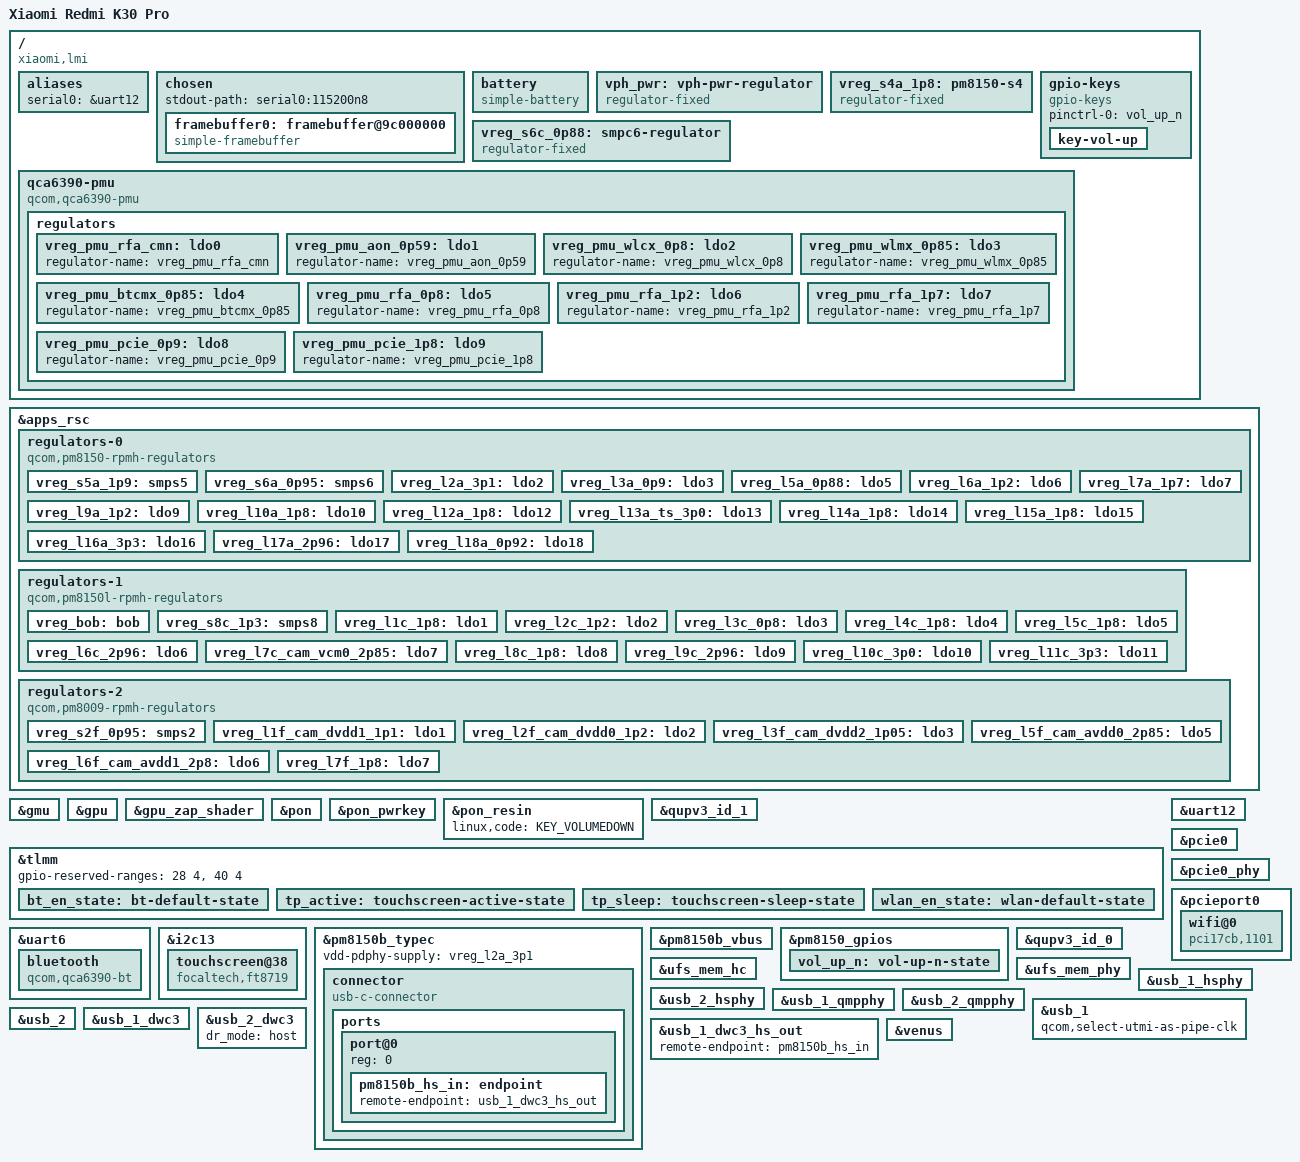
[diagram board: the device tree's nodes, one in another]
// SPDX-License-Identifier: BSD-3-Clause
/*
 * Copyright (c) 2020, The Linux Foundation. All rights reserved.
 * Copyright (c) 2026 OpenAI
 */

/dts-v1/;

#include <dt-bindings/arm/qcom,ids.h>
#include <dt-bindings/interrupt-controller/irq.h>
#include <dt-bindings/regulator/qcom,rpmh-regulator.h>
#include <dt-bindings/usb/pd.h>
#include "sm8250.dtsi"
#include "pm8150.dtsi"
#include "pm8150b.dtsi"
#include "pm8150l.dtsi"

/ {
	model = "Xiaomi Redmi K30 Pro";
	compatible = "xiaomi,lmi", "qcom,sm8250";

	/* Required by the Xiaomi bootloader to match this SM8250 board. */
	qcom,msm-id = <QCOM_ID_SM8250 0x20001>;

	chassis-type = "handset";

	aliases {
		serial0 = &uart12;
	};

	chosen {
		#address-cells = <2>;
		#size-cells = <2>;
		ranges;

		stdout-path = "serial0:115200n8";

		framebuffer0: framebuffer@9c000000 {
			compatible = "simple-framebuffer";
			reg = <0x0 0x9c000000 0x0 0x02300000>;
			width = <1080>;
			height = <2400>;
			stride = <4352>;
			format = "a8r8g8b8";
		};
	};

	battery: battery {
		compatible = "simple-battery";
		charge-full-design-microamp-hours = <4700000>;
		energy-full-design-microwatt-hours = <17500000>;
		voltage-min-design-microvolt = <3400000>;
		voltage-max-design-microvolt = <4460000>;
	};

	vph_pwr: vph-pwr-regulator {
		compatible = "regulator-fixed";
		regulator-name = "vph_pwr";
		regulator-min-microvolt = <3700000>;
		regulator-max-microvolt = <3700000>;
	};

	vreg_s4a_1p8: pm8150-s4 {
		compatible = "regulator-fixed";
		regulator-name = "vreg_s4a_1p8";

		regulator-min-microvolt = <1800000>;
		regulator-max-microvolt = <1800000>;

		regulator-always-on;
		regulator-boot-on;

		vin-supply = <&vph_pwr>;
	};

	vreg_s6c_0p88: smpc6-regulator {
		compatible = "regulator-fixed";
		regulator-name = "vreg_s6c_0p88";

		regulator-min-microvolt = <880000>;
		regulator-max-microvolt = <880000>;
		regulator-always-on;
		vin-supply = <&vph_pwr>;
	};

	gpio-keys {
		compatible = "gpio-keys";
		pinctrl-0 = <&vol_up_n>;
		pinctrl-names = "default";

		key-vol-up {
			label = "Volume Up";
			linux,code = <KEY_VOLUMEUP>;
			gpios = <&pm8150_gpios 6 GPIO_ACTIVE_LOW>;
		};
	};

	qca6390-pmu {
		compatible = "qcom,qca6390-pmu";

		pinctrl-0 = <&bt_en_state>, <&wlan_en_state>;
		pinctrl-names = "default";

		vddaon-supply = <&vreg_s6a_0p95>;
		vddpmu-supply = <&vreg_s6a_0p95>;
		vddrfa0p95-supply = <&vreg_s6a_0p95>;
		vddrfa1p3-supply = <&vreg_s8c_1p3>;
		vddrfa1p9-supply = <&vreg_s5a_1p9>;
		vddpcie1p3-supply = <&vreg_s8c_1p3>;
		vddpcie1p9-supply = <&vreg_s5a_1p9>;
		vddio-supply = <&vreg_s4a_1p8>;

		wlan-enable-gpios = <&tlmm 20 GPIO_ACTIVE_HIGH>;
		bt-enable-gpios = <&tlmm 21 GPIO_ACTIVE_HIGH>;

		regulators {
			vreg_pmu_rfa_cmn: ldo0 {
				regulator-name = "vreg_pmu_rfa_cmn";
			};
			vreg_pmu_aon_0p59: ldo1 {
				regulator-name = "vreg_pmu_aon_0p59";
			};
			vreg_pmu_wlcx_0p8: ldo2 {
				regulator-name = "vreg_pmu_wlcx_0p8";
			};
			vreg_pmu_wlmx_0p85: ldo3 {
				regulator-name = "vreg_pmu_wlmx_0p85";
			};
			vreg_pmu_btcmx_0p85: ldo4 {
				regulator-name = "vreg_pmu_btcmx_0p85";
			};
			vreg_pmu_rfa_0p8: ldo5 {
				regulator-name = "vreg_pmu_rfa_0p8";
			};
			vreg_pmu_rfa_1p2: ldo6 {
				regulator-name = "vreg_pmu_rfa_1p2";
			};
			vreg_pmu_rfa_1p7: ldo7 {
				regulator-name = "vreg_pmu_rfa_1p7";
			};
			vreg_pmu_pcie_0p9: ldo8 {
				regulator-name = "vreg_pmu_pcie_0p9";
			};
			vreg_pmu_pcie_1p8: ldo9 {
				regulator-name = "vreg_pmu_pcie_1p8";
			};
		};
	};
};

&apps_rsc {
	regulators-0 {
		compatible = "qcom,pm8150-rpmh-regulators";
		qcom,pmic-id = "a";

		vdd-s1-supply = <&vph_pwr>;
		vdd-s2-supply = <&vph_pwr>;
		vdd-s3-supply = <&vph_pwr>;
		vdd-s4-supply = <&vph_pwr>;
		vdd-s5-supply = <&vph_pwr>;
		vdd-s6-supply = <&vph_pwr>;
		vdd-s7-supply = <&vph_pwr>;
		vdd-s8-supply = <&vph_pwr>;
		vdd-s9-supply = <&vph_pwr>;
		vdd-s10-supply = <&vph_pwr>;
		vdd-l1-l8-l11-supply = <&vreg_s6c_0p88>;
		vdd-l2-l10-supply = <&vreg_bob>;
		vdd-l3-l4-l5-l18-supply = <&vreg_s6a_0p95>;
		vdd-l6-l9-supply = <&vreg_s8c_1p3>;
		vdd-l7-l12-l14-l15-supply = <&vreg_s5a_1p9>;
		vdd-l13-l16-l17-supply = <&vreg_bob>;

		vreg_s5a_1p9: smps5 {
			regulator-name = "vreg_s5a_1p9";
			regulator-min-microvolt = <1824000>;
			regulator-max-microvolt = <2000000>;
			regulator-initial-mode = <RPMH_REGULATOR_MODE_HPM>;
		};

		vreg_s6a_0p95: smps6 {
			regulator-name = "vreg_s6a_0p95";
			regulator-min-microvolt = <600000>;
			regulator-max-microvolt = <1128000>;
			regulator-initial-mode = <RPMH_REGULATOR_MODE_HPM>;
		};

		vreg_l2a_3p1: ldo2 {
			regulator-name = "vreg_l2a_3p1";
			regulator-min-microvolt = <3072000>;
			regulator-max-microvolt = <3072000>;
			regulator-initial-mode = <RPMH_REGULATOR_MODE_HPM>;
		};

		vreg_l3a_0p9: ldo3 {
			regulator-name = "vreg_l3a_0p9";
			regulator-min-microvolt = <928000>;
			regulator-max-microvolt = <932000>;
			regulator-initial-mode = <RPMH_REGULATOR_MODE_HPM>;
		};

		vreg_l5a_0p88: ldo5 {
			regulator-name = "vreg_l5a_0p88";
			regulator-min-microvolt = <880000>;
			regulator-max-microvolt = <880000>;
			regulator-initial-mode = <RPMH_REGULATOR_MODE_HPM>;
		};

		vreg_l6a_1p2: ldo6 {
			regulator-name = "vreg_l6a_1p2";
			regulator-min-microvolt = <1200000>;
			regulator-max-microvolt = <1200000>;
			regulator-initial-mode = <RPMH_REGULATOR_MODE_HPM>;
		};

		vreg_l7a_1p7: ldo7 {
			regulator-name = "vreg_l7a_1p7";
			regulator-min-microvolt = <1704000>;
			regulator-max-microvolt = <1800000>;
			regulator-initial-mode = <RPMH_REGULATOR_MODE_HPM>;
		};

		vreg_l9a_1p2: ldo9 {
			regulator-name = "vreg_l9a_1p2";
			regulator-min-microvolt = <1200000>;
			regulator-max-microvolt = <1200000>;
			regulator-initial-mode = <RPMH_REGULATOR_MODE_HPM>;
		};

		vreg_l10a_1p8: ldo10 {
			regulator-name = "vreg_l10a_1p8";
			regulator-min-microvolt = <1800000>;
			regulator-max-microvolt = <2960000>;
			regulator-initial-mode = <RPMH_REGULATOR_MODE_HPM>;
		};

		vreg_l12a_1p8: ldo12 {
			regulator-name = "vreg_l12a_1p8";
			regulator-min-microvolt = <1800000>;
			regulator-max-microvolt = <1800000>;
			regulator-initial-mode = <RPMH_REGULATOR_MODE_HPM>;
		};

		vreg_l13a_ts_3p0: ldo13 {
			regulator-name = "vreg_l13a_ts_3p0";
			regulator-min-microvolt = <3008000>;
			regulator-max-microvolt = <3008000>;
			regulator-initial-mode = <RPMH_REGULATOR_MODE_HPM>;
		};

		vreg_l14a_1p8: ldo14 {
			regulator-name = "vreg_l14a_1p8";
			regulator-min-microvolt = <1800000>;
			regulator-max-microvolt = <1880000>;
			regulator-initial-mode = <RPMH_REGULATOR_MODE_HPM>;
		};

		vreg_l15a_1p8: ldo15 {
			regulator-name = "vreg_l15a_1p8";
			regulator-min-microvolt = <1800000>;
			regulator-max-microvolt = <1800000>;
			regulator-initial-mode = <RPMH_REGULATOR_MODE_HPM>;
		};

		vreg_l16a_3p3: ldo16 {
			regulator-name = "vreg_l16a_3p3";
			regulator-min-microvolt = <3024000>;
			regulator-max-microvolt = <3304000>;
			regulator-initial-mode = <RPMH_REGULATOR_MODE_HPM>;
		};

		vreg_l17a_2p96: ldo17 {
			regulator-name = "vreg_l17a_2p96";
			regulator-min-microvolt = <2496000>;
			regulator-max-microvolt = <3008000>;
			regulator-initial-mode = <RPMH_REGULATOR_MODE_HPM>;
		};

		vreg_l18a_0p92: ldo18 {
			regulator-name = "vreg_l18a_0p92";
			regulator-min-microvolt = <800000>;
			regulator-max-microvolt = <920000>;
			regulator-initial-mode = <RPMH_REGULATOR_MODE_HPM>;
		};
	};

	regulators-1 {
		compatible = "qcom,pm8150l-rpmh-regulators";
		qcom,pmic-id = "c";

		vdd-s1-supply = <&vph_pwr>;
		vdd-s2-supply = <&vph_pwr>;
		vdd-s3-supply = <&vph_pwr>;
		vdd-s4-supply = <&vph_pwr>;
		vdd-s5-supply = <&vph_pwr>;
		vdd-s6-supply = <&vph_pwr>;
		vdd-s7-supply = <&vph_pwr>;
		vdd-s8-supply = <&vph_pwr>;
		vdd-l1-l8-supply = <&vreg_s4a_1p8>;
		vdd-l2-l3-supply = <&vreg_s8c_1p3>;
		vdd-l4-l5-l6-supply = <&vreg_bob>;
		vdd-l7-l11-supply = <&vreg_bob>;
		vdd-l9-l10-supply = <&vreg_bob>;
		vdd-bob-supply = <&vph_pwr>;

		vreg_bob: bob {
			regulator-name = "vreg_bob";
			regulator-min-microvolt = <3008000>;
			regulator-max-microvolt = <3960000>;
			regulator-initial-mode = <RPMH_REGULATOR_MODE_AUTO>;
		};

		vreg_s8c_1p3: smps8 {
			regulator-name = "vreg_s8c_1p3";
			regulator-min-microvolt = <1200000>;
			regulator-max-microvolt = <1400000>;
			regulator-initial-mode = <RPMH_REGULATOR_MODE_HPM>;
		};

		vreg_l1c_1p8: ldo1 {
			regulator-name = "vreg_l1c_1p8";
			regulator-min-microvolt = <1800000>;
			regulator-max-microvolt = <1800000>;
			regulator-initial-mode = <RPMH_REGULATOR_MODE_HPM>;
		};

		vreg_l2c_1p2: ldo2 {
			regulator-name = "vreg_l2c_1p2";
			regulator-min-microvolt = <1200000>;
			regulator-max-microvolt = <1304000>;
			regulator-initial-mode = <RPMH_REGULATOR_MODE_HPM>;
		};

		vreg_l3c_0p8: ldo3 {
			regulator-name = "vreg_l3c_0p8";
			regulator-min-microvolt = <800000>;
			regulator-max-microvolt = <1200000>;
			regulator-initial-mode = <RPMH_REGULATOR_MODE_HPM>;
		};

		vreg_l4c_1p8: ldo4 {
			regulator-name = "vreg_l4c_1p8";
			regulator-min-microvolt = <1800000>;
			regulator-max-microvolt = <2800000>;
			regulator-initial-mode = <RPMH_REGULATOR_MODE_HPM>;
		};

		vreg_l5c_1p8: ldo5 {
			regulator-name = "vreg_l5c_1p8";
			regulator-min-microvolt = <1800000>;
			regulator-max-microvolt = <2800000>;
			regulator-initial-mode = <RPMH_REGULATOR_MODE_HPM>;
		};

		vreg_l6c_2p96: ldo6 {
			regulator-name = "vreg_l6c_2p96";
			regulator-min-microvolt = <1800000>;
			regulator-max-microvolt = <2960000>;
			regulator-initial-mode = <RPMH_REGULATOR_MODE_HPM>;
		};

		vreg_l7c_cam_vcm0_2p85: ldo7 {
			regulator-name = "vreg_l7c_cam_vcm0_2p85";
			regulator-min-microvolt = <2856000>;
			regulator-max-microvolt = <3104000>;
			regulator-initial-mode = <RPMH_REGULATOR_MODE_HPM>;
		};

		vreg_l8c_1p8: ldo8 {
			regulator-name = "vreg_l8c_1p8";
			regulator-min-microvolt = <1800000>;
			regulator-max-microvolt = <1800000>;
			regulator-initial-mode = <RPMH_REGULATOR_MODE_HPM>;
		};

		vreg_l9c_2p96: ldo9 {
			regulator-name = "vreg_l9c_2p96";
			regulator-min-microvolt = <2704000>;
			regulator-max-microvolt = <2960000>;
			regulator-initial-mode = <RPMH_REGULATOR_MODE_HPM>;
		};

		vreg_l10c_3p0: ldo10 {
			regulator-name = "vreg_l10c_3p0";
			regulator-min-microvolt = <3000000>;
			regulator-max-microvolt = <3312000>;
			regulator-initial-mode = <RPMH_REGULATOR_MODE_HPM>;
		};

		vreg_l11c_3p3: ldo11 {
			regulator-name = "vreg_l11c_3p3";
			regulator-min-microvolt = <3104000>;
			regulator-max-microvolt = <3312000>;
			regulator-initial-mode = <RPMH_REGULATOR_MODE_HPM>;
		};
	};

	regulators-2 {
		compatible = "qcom,pm8009-rpmh-regulators";
		qcom,pmic-id = "f";

		vdd-s1-supply = <&vph_pwr>;
		vdd-s2-supply = <&vreg_bob>;
		vdd-l2-supply = <&vreg_s8c_1p3>;
		vdd-l5-l6-supply = <&vreg_bob>;
		vdd-l7-supply = <&vreg_s4a_1p8>;

		vreg_s2f_0p95: smps2 {
			regulator-name = "vreg_s2f_0p95";
			regulator-min-microvolt = <900000>;
			regulator-max-microvolt = <952000>;
			regulator-initial-mode = <RPMH_REGULATOR_MODE_HPM>;
		};

		vreg_l1f_cam_dvdd1_1p1: ldo1 {
			regulator-name = "vreg_l1f_cam_dvdd1_1p1";
			regulator-min-microvolt = <1104000>;
			regulator-max-microvolt = <1104000>;
			regulator-initial-mode = <RPMH_REGULATOR_MODE_HPM>;
		};

		vreg_l2f_cam_dvdd0_1p2: ldo2 {
			regulator-name = "vreg_l2f_cam_dvdd0_1p2";
			regulator-min-microvolt = <1200000>;
			regulator-max-microvolt = <1200000>;
			regulator-initial-mode = <RPMH_REGULATOR_MODE_HPM>;
		};

		vreg_l3f_cam_dvdd2_1p05: ldo3 {
			regulator-name = "vreg_l3f_cam_dvdd2_1p05";
			regulator-min-microvolt = <1056000>;
			regulator-max-microvolt = <1056000>;
			regulator-initial-mode = <RPMH_REGULATOR_MODE_HPM>;
		};

		vreg_l5f_cam_avdd0_2p85: ldo5 {
			regulator-name = "vreg_l5f_cam_avdd0_2p85";
			regulator-min-microvolt = <2800000>;
			regulator-max-microvolt = <3000000>;
			regulator-initial-mode = <RPMH_REGULATOR_MODE_HPM>;
		};

		vreg_l6f_cam_avdd1_2p8: ldo6 {
			regulator-name = "vreg_l6f_cam_avdd1_2p8";
			regulator-min-microvolt = <2800000>;
			regulator-max-microvolt = <3000000>;
			regulator-initial-mode = <RPMH_REGULATOR_MODE_HPM>;
		};

		vreg_l7f_1p8: ldo7 {
			regulator-name = "vreg_l7f_1p8";
			regulator-min-microvolt = <1800000>;
			regulator-max-microvolt = <1800000>;
			regulator-initial-mode = <RPMH_REGULATOR_MODE_HPM>;
		};
	};
};

&gmu {
	status = "okay";
};

&gpu {
	status = "okay";
};

&gpu_zap_shader {
	firmware-name = "qcom/sm8250/xiaomi/lmi/a650_zap.mbn";
};

&pon {
	mode-bootloader = <0x2>;
	mode-recovery = <0x1>;
};

&pon_pwrkey {
	status = "okay";
};

&pon_resin {
	status = "okay";

	linux,code = <KEY_VOLUMEDOWN>;
};

&qupv3_id_1 {
	status = "okay";
};

&tlmm {
	gpio-reserved-ranges = <28 4>, <40 4>;

	bt_en_state: bt-default-state {
		pins = "gpio21";
		function = "gpio";
		drive-strength = <16>;
		output-low;
		bias-pull-up;
	};

	tp_active: touchscreen-active-state {
		pins = "gpio38", "gpio39";
		function = "gpio";
		drive-strength = <16>;
		bias-pull-up;
	};

	tp_sleep: touchscreen-sleep-state {
		pins = "gpio38", "gpio39";
		function = "gpio";
		drive-strength = <2>;
		bias-pull-up;
	};

	wlan_en_state: wlan-default-state {
		pins = "gpio20";
		function = "gpio";
		drive-strength = <16>;
		output-low;
		bias-pull-up;
	};
};

&uart6 {
	status = "okay";

	bluetooth {
		compatible = "qcom,qca6390-bt";

		vddrfacmn-supply = <&vreg_pmu_rfa_cmn>;
		vddaon-supply = <&vreg_pmu_aon_0p59>;
		vddbtcmx-supply = <&vreg_pmu_btcmx_0p85>;
		vddrfa0p8-supply = <&vreg_pmu_rfa_0p8>;
		vddrfa1p2-supply = <&vreg_pmu_rfa_1p2>;
		vddrfa1p7-supply = <&vreg_pmu_rfa_1p7>;
	};
};

&uart12 {
	status = "okay";
};

&i2c13 {
	status = "okay";

	touchscreen@38 {
		compatible = "focaltech,ft8719";
		reg = <0x38>;

		interrupt-parent = <&tlmm>;
		interrupts = <39 IRQ_TYPE_EDGE_FALLING>;
		reset-gpios = <&tlmm 38 GPIO_ACTIVE_LOW>;

		pinctrl-0 = <&tp_active>;
		pinctrl-1 = <&tp_sleep>;
		pinctrl-names = "default", "sleep";

		touchscreen-size-x = <1080>;
		touchscreen-size-y = <2400>;

		vcc-supply = <&vreg_l10c_3p0>;
		iovcc-supply = <&vreg_l1c_1p8>;
	};
};

&pcie0 {
	vdda-supply = <&vreg_l9a_1p2>;
	vddpe-3v3-supply = <&vreg_l11c_3p3>;
	status = "okay";
};

&pcie0_phy {
	vdda-phy-supply = <&vreg_s6c_0p88>;
	vdda-pll-supply = <&vreg_l9a_1p2>;
	status = "okay";
};

&pcieport0 {
	wifi@0 {
		compatible = "pci17cb,1101";
		reg = <0x10000 0x0 0x0 0x0 0x0>;

		vddrfacmn-supply = <&vreg_pmu_rfa_cmn>;
		vddaon-supply = <&vreg_pmu_aon_0p59>;
		vddwlcx-supply = <&vreg_pmu_wlcx_0p8>;
		vddwlmx-supply = <&vreg_pmu_wlmx_0p85>;
		vddrfa0p8-supply = <&vreg_pmu_rfa_0p8>;
		vddrfa1p2-supply = <&vreg_pmu_rfa_1p2>;
		vddrfa1p7-supply = <&vreg_pmu_rfa_1p7>;
		vddpcie0p9-supply = <&vreg_pmu_pcie_0p9>;
		vddpcie1p8-supply = <&vreg_pmu_pcie_1p8>;
	};
};

&pm8150b_typec {
	vdd-pdphy-supply = <&vreg_l2a_3p1>;
	status = "okay";

	connector {
		compatible = "usb-c-connector";

		data-role = "dual";
		op-sink-microwatt = <10000000>;
		power-role = "dual";
		self-powered;
		vbus-supply = <&pm8150b_vbus>;

		source-pdos = <PDO_FIXED(5000, 3000,
				PDO_FIXED_DUAL_ROLE |
				PDO_FIXED_USB_COMM |
				PDO_FIXED_DATA_SWAP)>;
		sink-pdos = <PDO_FIXED(5000, 3000,
			       PDO_FIXED_DUAL_ROLE |
			       PDO_FIXED_USB_COMM |
			       PDO_FIXED_DATA_SWAP)
			     PDO_VAR(5000, 12000, 5000)>;

		ports {
			#address-cells = <1>;
			#size-cells = <0>;

			port@0 {
				reg = <0>;

				pm8150b_hs_in: endpoint {
					remote-endpoint = <&usb_1_dwc3_hs_out>;
				};
			};
		};
	};
};

&pm8150b_vbus {
	regulator-min-microamp = <500000>;
	regulator-max-microamp = <3000000>;
	status = "okay";
};

&pm8150_gpios {
	vol_up_n: vol-up-n-state {
		pins = "gpio6";
		function = "normal";
		power-source = <1>;
		input-enable;
		bias-pull-up;
	};
};

&qupv3_id_0 {
	status = "okay";
};

&ufs_mem_hc {
	status = "okay";

	vcc-supply = <&vreg_l17a_2p96>;
	vcc-max-microamp = <800000>;
	vccq-supply = <&vreg_l6a_1p2>;
	vccq-max-microamp = <800000>;
	vccq2-supply = <&vreg_s4a_1p8>;
	vccq2-max-microamp = <800000>;
};

&ufs_mem_phy {
	status = "okay";

	vdda-phy-supply = <&vreg_l5a_0p88>;
	vdda-pll-supply = <&vreg_l9a_1p2>;
};

&usb_1_hsphy {
	status = "okay";
	vdda-pll-supply = <&vreg_l5a_0p88>;
	vdda33-supply = <&vreg_l2a_3p1>;
	vdda18-supply = <&vreg_l12a_1p8>;
};

&usb_2_hsphy {
	status = "okay";
	vdda-pll-supply = <&vreg_l5a_0p88>;
	vdda33-supply = <&vreg_l2a_3p1>;
	vdda18-supply = <&vreg_l12a_1p8>;
};

&usb_1_qmpphy {
	status = "okay";
	vdda-phy-supply = <&vreg_l9a_1p2>;
	vdda-pll-supply = <&vreg_l18a_0p92>;
};

&usb_2_qmpphy {
	status = "okay";
	vdda-phy-supply = <&vreg_l9a_1p2>;
	vdda-pll-supply = <&vreg_l18a_0p92>;
};

&usb_1 {
	qcom,select-utmi-as-pipe-clk;
	status = "okay";
};

&usb_2 {
	status = "okay";
};

&usb_1_dwc3 {
	dr_mode = "otg";
	maximum-speed = "high-speed";
	phys = <&usb_1_hsphy>;
	phy-names = "usb2-phy";
	usb-role-switch;
};

&usb_1_dwc3_hs_out {
	remote-endpoint = <&pm8150b_hs_in>;
};

&usb_2_dwc3 {
	dr_mode = "host";
};

&venus {
	firmware-name = "qcom/sm8250/xiaomi/lmi/venus.mbn";
	status = "okay";
};
